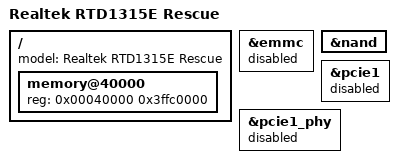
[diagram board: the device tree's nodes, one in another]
// SPDX-License-Identifier: GPL-2.0
/*
 * Copyright (c) 2023 Realtek Semiconductor Corp.
 */

/dts-v1/;

#include "rtd1325-rescue.dtsi"

/ {
	model = "Realtek RTD1315E Rescue";

	memory@40000 {
		device_type = "memory";
		reg = <0x00040000 0x3ffc0000>; /* 1 GiB */
	};
};

&emmc {
	status = "disabled";
};

&nand {
	status = "okay";
};

&pcie1 {
	status = "disabled";
};

&pcie1_phy {
	status = "disabled";
};

